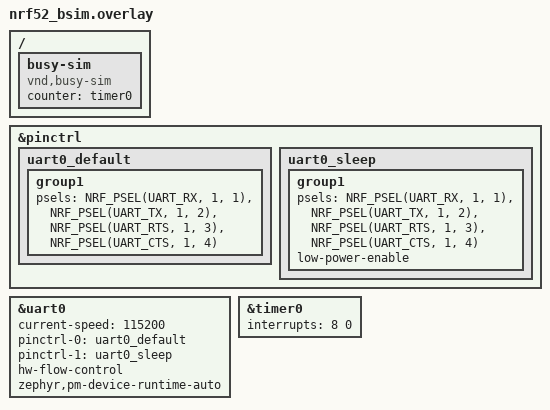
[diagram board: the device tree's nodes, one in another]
/* SPDX-License-Identifier: Apache-2.0 */

&pinctrl {
	uart0_default: uart0_default {
		group1 {
			psels = <NRF_PSEL(UART_RX, 1, 1)>,
				<NRF_PSEL(UART_TX, 1, 2)>,
				<NRF_PSEL(UART_RTS, 1, 3)>,
				<NRF_PSEL(UART_CTS, 1, 4)>;
		};
	};

	uart0_sleep: uart0_sleep {
		group1 {
			psels = <NRF_PSEL(UART_RX, 1, 1)>,
				<NRF_PSEL(UART_TX, 1, 2)>,
				<NRF_PSEL(UART_RTS, 1, 3)>,
				<NRF_PSEL(UART_CTS, 1, 4)>;
			low-power-enable;
		};
	};
};

dut: &uart0 {
	status = "okay";
	current-speed = <115200>;
	pinctrl-0 = <&uart0_default>;
	pinctrl-1 = <&uart0_sleep>;
	pinctrl-names = "default", "sleep";
	hw-flow-control;
	zephyr,pm-device-runtime-auto;
};

&timer0 {
	status = "okay";
	interrupts = <8 0>;
};

/ {
	busy-sim {
		compatible = "vnd,busy-sim";
		status = "okay";
		counter = <&timer0>;
	};
};
